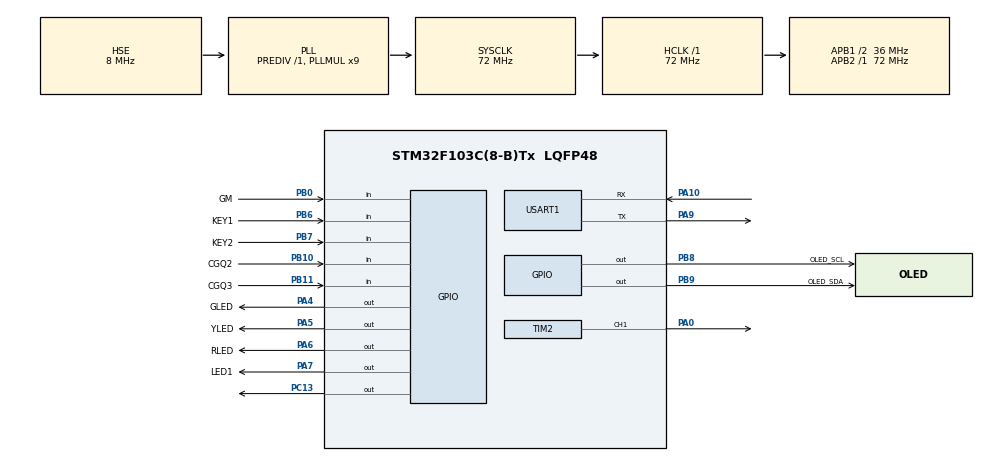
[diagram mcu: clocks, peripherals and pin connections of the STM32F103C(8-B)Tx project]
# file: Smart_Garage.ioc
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Mcu.Family=STM32F1
Mcu.Name=STM32F103C(8-B)Tx
Mcu.Package=LQFP48
NVIC.PriorityGroup=NVIC_PRIORITYGROUP_4
NVIC.TIM4_IRQn=true\:15\:0\:false\:false\:true\:false\:true\:true
NVIC.TimeBase=TIM4_IRQn
NVIC.TimeBaseIP=TIM4
NVIC.USART1_IRQn=true\:0\:0\:false\:false\:true\:true\:true\:true
PA0-WKUP.Signal=S_TIM2_CH1_ETR
PA10.Mode=Asynchronous
PA10.Signal=USART1_RX
PA13.Mode=Serial_Wire
PA13.Signal=SYS_JTMS-SWDIO
PA14.Mode=Serial_Wire
PA14.Signal=SYS_JTCK-SWCLK
PA4.GPIO_Label=GLED
PA4.Signal=GPIO_Output
PA5.GPIO_Label=YLED
PA5.Signal=GPIO_Output
PA6.GPIO_Label=RLED
PA6.Signal=GPIO_Output
PA7.GPIO_Label=LED1
PA7.Signal=GPIO_Output
PA9.Mode=Asynchronous
PA9.Signal=USART1_TX
PB0.GPIO_Label=GM
PB0.Signal=GPIO_Input
PB10.GPIO_Label=CGQ2
PB10.Signal=GPIO_Input
PB11.GPIO_Label=CGQ3
PB11.Signal=GPIO_Input
PB6.GPIO_Label=KEY1
PB6.GPIO_PuPd=GPIO_PULLUP
PB6.Signal=GPIO_Input
PB7.GPIO_Label=KEY2
PB7.GPIO_PuPd=GPIO_PULLUP
PB7.Signal=GPIO_Input
PB8.GPIO_Label=OLED_SCL
PB8.GPIO_ModeDefaultOutputPP=GPIO_MODE_OUTPUT_OD
PB8.GPIO_PuPd=GPIO_NOPULL
PB8.Signal=GPIO_Output
PB9.GPIO_Label=OLED_SDA
PB9.GPIO_ModeDefaultOutputPP=GPIO_MODE_OUTPUT_OD
PB9.GPIO_PuPd=GPIO_NOPULL
PB9.Signal=GPIO_Output
PC13-TAMPER-RTC.Signal=GPIO_Output
PD0-OSC_IN.Mode=HSE-External-Oscillator
PD0-OSC_IN.Signal=RCC_OSC_IN
PD1-OSC_OUT.Mode=HSE-External-Oscillator
PD1-OSC_OUT.Signal=RCC_OSC_OUT
ProjectManager.HeapSize=0x200
ProjectManager.StackSize=0x400
ProjectManager.TargetToolchain=MDK-ARM V5.32
RCC.AHBFreq_Value=72000000
RCC.APB1CLKDivider=RCC_HCLK_DIV2
RCC.APB1Freq_Value=36000000
RCC.APB1TimFreq_Value=72000000
RCC.APB2Freq_Value=72000000
RCC.APB2TimFreq_Value=72000000
RCC.HCLKFreq_Value=72000000
RCC.PLLMUL=RCC_PLL_MUL9
RCC.PLLSourceVirtual=RCC_PLLSOURCE_HSE
RCC.SYSCLKFreq_VALUE=72000000
RCC.SYSCLKSource=RCC_SYSCLKSOURCE_PLLCLK
RCC.USBFreq_Value=72000000
SH.S_TIM2_CH1_ETR.0=TIM2_CH1,PWM Generation1 CH1
TIM2.AutoReloadPreload=TIM_AUTORELOAD_PRELOAD_ENABLE
TIM2.Channel-PWM\ Generation1\ CH1=TIM_CHANNEL_1
TIM2.Period=2000-1
TIM2.Prescaler=720-1
USART1.VirtualMode=VM_ASYNC
VP_SYS_VS_tim4.Mode=TIM4
VP_TIM2_VS_ClockSourceINT.Mode=Internal
board=custom

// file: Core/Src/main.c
/* USER CODE BEGIN Header */
/**
  ******************************************************************************
  * @file           : main.c
  * @brief          : Main program body
  ******************************************************************************
  * @attention
  *
  * Copyright (c) 2025 STMicroelectronics.
  * All rights reserved.
  *
  * This software is licensed under terms that can be found in the LICENSE file
  * in the root directory of this software component.
  * If no LICENSE file comes with this software, it is provided AS-IS.
  *
  ******************************************************************************
  */
/* USER CODE END Header */
#include "main.h"
#include "tim.h"
#include "usart.h"
#include "gpio.h"

/* USER CODE BEGIN Includes */
#include "app.h"
// #include "flash_storage.h"
/* USER CODE END Includes */

/* USER CODE BEGIN PM */
// void PVD_Config(void) {
//     PWR_PVDTypeDef sConfigPVD;

//     // 1. 使能电源时钟
//     __HAL_RCC_PWR_CLK_ENABLE();

//     // 2. 配置 PVD 级别 (Level 7 约为 2.9V)
//     sConfigPVD.PVDLevel = PWR_PVDLEVEL_7;
//     sConfigPVD.Mode = PWR_PVD_MODE_IT_FALLING; // 电压下降时触发中断
//     HAL_PWR_ConfigPVD(&sConfigPVD);

//     // 3. 使能 PVD
//     HAL_PWR_EnablePVD();

//     // 4. 手动开启 NVIC 中断 (PVD 对应的是 EXTI Line 16)
//     HAL_NVIC_SetPriority(PVD_IRQn, 0, 0);
//     HAL_NVIC_EnableIRQ(PVD_IRQn);
// }
/* USER CODE END PM */

void SystemClock_Config(void);

int main(void)
{

  /* MCU Configuration--------------------------------------------------------*/

  /* Reset of all peripherals, Initializes the Flash interface and the Systick. */
  HAL_Init();

  /* Configure the system clock */
  SystemClock_Config();

  /* Initialize all configured peripherals */
  MX_GPIO_Init();
  MX_USART1_UART_Init();
  MX_TIM2_Init();
  /* USER CODE BEGIN 2 */
  // PVD_Config(); // 配置电压检测功能
	app_init();
  /* USER CODE END 2 */

  /* Infinite loop */
  while (1)
  {

  }
}

void SystemClock_Config(void)
{
  RCC_OscInitTypeDef RCC_OscInitStruct = {0};
  RCC_ClkInitTypeDef RCC_ClkInitStruct = {0};

  /** Initializes the RCC Oscillators according to the specified parameters
  * in the RCC_OscInitTypeDef structure.
  */
  RCC_OscInitStruct.OscillatorType = RCC_OSCILLATORTYPE_HSE;
  RCC_OscInitStruct.HSEState = RCC_HSE_ON;
  RCC_OscInitStruct.HSEPredivValue = RCC_HSE_PREDIV_DIV1;
  RCC_OscInitStruct.HSIState = RCC_HSI_ON;
  RCC_OscInitStruct.PLL.PLLState = RCC_PLL_ON;
  RCC_OscInitStruct.PLL.PLLSource = RCC_PLLSOURCE_HSE;
  RCC_OscInitStruct.PLL.PLLMUL = RCC_PLL_MUL9;
  if (HAL_RCC_OscConfig(&RCC_OscInitStruct) != HAL_OK)
  {
    Error_Handler();
  }

  /** Initializes the CPU, AHB and APB buses clocks
  */
  RCC_ClkInitStruct.ClockType = RCC_CLOCKTYPE_HCLK|RCC_CLOCKTYPE_SYSCLK
                              |RCC_CLOCKTYPE_PCLK1|RCC_CLOCKTYPE_PCLK2;
  RCC_ClkInitStruct.SYSCLKSource = RCC_SYSCLKSOURCE_PLLCLK;
  RCC_ClkInitStruct.AHBCLKDivider = RCC_SYSCLK_DIV1;
  RCC_ClkInitStruct.APB1CLKDivider = RCC_HCLK_DIV2;
  RCC_ClkInitStruct.APB2CLKDivider = RCC_HCLK_DIV1;

  if (HAL_RCC_ClockConfig(&RCC_ClkInitStruct, FLASH_LATENCY_2) != HAL_OK)
  {
    Error_Handler();
  }
}

/* USER CODE BEGIN 4 */

// void HAL_PWR_PVDCallback(void)
// {
//     all_vehicles_to_flash(); // 在电压异常时立即保存数据，防止数据丢失
// }

/* USER CODE END 4 */

void HAL_TIM_PeriodElapsedCallback(TIM_HandleTypeDef *htim)
{
  if (htim->Instance == TIM4) {
    HAL_IncTick();
  }
}

void Error_Handler(void)
{
  __disable_irq();
  while (1)
  {
  }
}
